# EPM register map
Vendor: Texas Instruments
Peripheral module from a debugger description file (folder omap36xx).
Registers are 32-bit, access per field, reset 0x0 unless marked. A register's access mark holds for its fields unless they carry their own. Offsets are as the file gives them; lines under a group give offsets from that group; [hi:lo] are bit positions; {n}, {i} and the like mark numbered series; 'fields as' and 'values as' point back to an identical list; <NAME> marks a mode.

## EPM
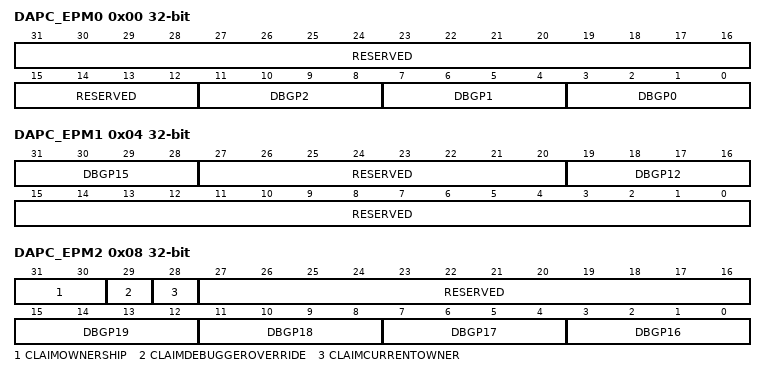
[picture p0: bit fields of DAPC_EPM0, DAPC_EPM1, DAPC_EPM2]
0x00 DAPC_EPM0 — Emulation pin manager register 0.
  [31:12] RESERVED ro — Read returns reset value.
  [11:8] DBGP2 rw — TRACECLK, TRACECTL and TRACEDATA[7:0] pins control
  [7:4] DBGP1 rw — EMU1 pin control
  [3:0] DBGP0 rw — EMU0 pin control
0x04 DAPC_EPM1 — Emulation pin manager register 1
  [31:28] DBGP15 rw — TRACEDATA[11] pin control
  [27:20] RESERVED ro — Read returns reset value.
  [19:16] DBGP12 rw — TRACEDATA[10:8] pin control
  [15:0] RESERVED ro — Read returns reset value.
0x08 DAPC_EPM2 — Emulation pin manager register 2
  [31:30] CLAIMOWNERSHIP rw — Read:Read to get current ownership status. The claim status encoding shall be (0=Available, 1=Claimed, 2=Enabled, 3=Reserved)Write:Send command to modify ownership state. A successful command would cause these bit values to reflect the new state.
  [29] CLAIMDEBUGGEROVERRIDE rw — Read:Reading from the DebuggerOverride bit returns a 1.Write:This qualifier bit is used with the debugger's CLAIM request. When written with DebuggerOverride=1, a claim request by the debugger is granted regardless of current ownership status of the unit. When written with DebuggerOverride=0, the claim request is granted only if the unit is available.
  [28] CLAIMCURRENTOWNER ro — This value reflects the unit ownership when the register is in a non-Available state.0=Debugger owns resource.1=Application owns resource
  [27:16] RESERVED ro — Read returns reset value.
  [4n-61:4n-64] DBGP{n} rw (n=16..19) — TRACEDATA[{n-4}] pin control
